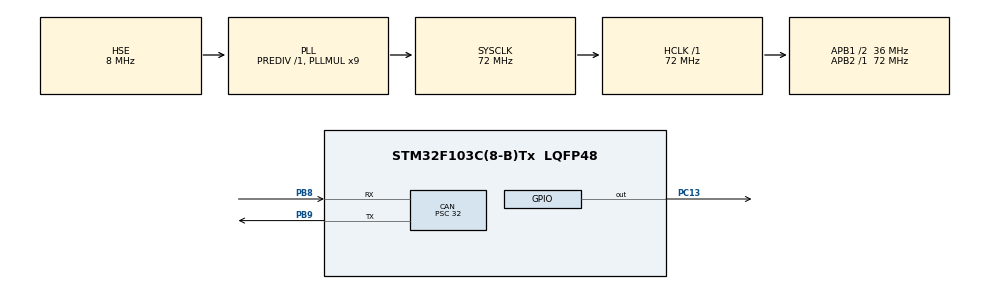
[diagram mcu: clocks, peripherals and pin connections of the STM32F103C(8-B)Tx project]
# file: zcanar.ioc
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CAN.BS1=CAN_BS1_2TQ
CAN.BS2=CAN_BS2_2TQ
CAN.CalculateBaudRate=225000
CAN.CalculateTimeBit=4444
CAN.CalculateTimeQuantum=888.8888888888889
CAN.Prescaler=32
Mcu.Family=STM32F1
Mcu.Name=STM32F103C(8-B)Tx
Mcu.Package=LQFP48
NVIC.CAN1_RX1_IRQn=true\:0\:0\:false\:false\:true\:true\:true\:true
NVIC.PriorityGroup=NVIC_PRIORITYGROUP_4
NVIC.USB_LP_CAN1_RX0_IRQn=true\:0\:0\:false\:false\:true\:true\:true\:true
PA13.Mode=Serial_Wire
PA13.Signal=SYS_JTMS-SWDIO
PA14.Mode=Serial_Wire
PA14.Signal=SYS_JTCK-SWCLK
PB8.Mode=CAN_Activate
PB8.Signal=CAN_RX
PB9.Mode=CAN_Activate
PB9.Signal=CAN_TX
PC13-TAMPER-RTC.Signal=GPIO_Output
PD0-OSC_IN.Mode=HSE-External-Oscillator
PD0-OSC_IN.Signal=RCC_OSC_IN
PD1-OSC_OUT.Mode=HSE-External-Oscillator
PD1-OSC_OUT.Signal=RCC_OSC_OUT
ProjectManager.HeapSize=0x200
ProjectManager.StackSize=0x400
ProjectManager.TargetToolchain=STM32CubeIDE
RCC.AHBFreq_Value=72000000
RCC.APB1CLKDivider=RCC_HCLK_DIV2
RCC.APB1Freq_Value=36000000
RCC.APB1TimFreq_Value=72000000
RCC.APB2Freq_Value=72000000
RCC.APB2TimFreq_Value=72000000
RCC.HCLKFreq_Value=72000000
RCC.PLLMUL=RCC_PLL_MUL9
RCC.PLLSourceVirtual=RCC_PLLSOURCE_HSE
RCC.SYSCLKFreq_VALUE=72000000
RCC.SYSCLKSource=RCC_SYSCLKSOURCE_PLLCLK
RCC.USBFreq_Value=72000000
board=custom

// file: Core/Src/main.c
/* USER CODE BEGIN Header */
/**
  ******************************************************************************
  * @file           : main.c
  * @brief          : Main program body
  ******************************************************************************
  * @attention
  *
  * Copyright (c) 2026 STMicroelectronics.
  * All rights reserved.
  *
  * This software is licensed under terms that can be found in the LICENSE file
  * in the root directory of this software component.
  * If no LICENSE file comes with this software, it is provided AS-IS.
  *
  ******************************************************************************
  */
/* USER CODE END Header */
#include "main.h"

/* USER CODE BEGIN Includes */
#include "stdio.h"
#include "string.h"
/* USER CODE END Includes */

CAN_HandleTypeDef hcan;

void SystemClock_Config(void);
static void MX_GPIO_Init(void);
static void MX_CAN_Init(void);

/* USER CODE BEGIN 0 */

struct controller{
	float P;
	float I;
	float D;
	float vel;
	float pos;
};

uint8_t senderID = 0xe0;

struct controller s1 = {2.0, 1.5, 0.005, 400, 11400};

CAN_TxHeaderTypeDef txHeader;
CAN_RxHeaderTypeDef rxHeader;

uint8_t txData[8];
uint8_t rxData[8];

uint32_t txMailbox;

void HAL_CAN_RxFifo1MsgPendingCallback(CAN_HandleTypeDef *hcan)
{

	HAL_CAN_GetRxMessage(hcan, CAN_RX_FIFO1, &rxHeader, rxData);
	if(rxHeader.RTR && rxHeader.StdId==0x7fe)
	{
		HAL_GPIO_TogglePin(GPIOC, GPIO_PIN_13);
		txHeader.DLC = 8;
		txHeader.IDE = CAN_ID_STD;
		txHeader.RTR = CAN_RTR_DATA;
		txHeader.StdId = 0x7fe;
		memset(txData, (uint8_t []){0,0,0,senderID|0},4);
		memcpy(&txData[4],&s1.P, 4);
		HAL_CAN_AddTxMessage(hcan, &txHeader, txData, &txMailbox);
		memset(txData, (uint8_t []){0,0,0,senderID|1},4);
		memcpy(&txData[4],&s1.I, 4);
		HAL_CAN_AddTxMessage(hcan, &txHeader, txData, &txMailbox);
		memset(txData, (uint8_t []){0,0,0,senderID|2},4);
		memcpy(&txData[4],&s1.D, 4);
		HAL_CAN_AddTxMessage(hcan, &txHeader, txData, &txMailbox);
	}
}

/* USER CODE END 0 */

int main(void)
{

  /* MCU Configuration--------------------------------------------------------*/

  /* Reset of all peripherals, Initializes the Flash interface and the Systick. */
  HAL_Init();

  /* Configure the system clock */
  SystemClock_Config();

  /* Initialize all configured peripherals */
  MX_GPIO_Init();
  MX_CAN_Init();
  /* USER CODE BEGIN 2 */
  HAL_CAN_Start(&hcan);
  /* USER CODE END 2 */

  /* Infinite loop */
  while (1)
  {

  }
}

void SystemClock_Config(void)
{
  RCC_OscInitTypeDef RCC_OscInitStruct = {0};
  RCC_ClkInitTypeDef RCC_ClkInitStruct = {0};

  /** Initializes the RCC Oscillators according to the specified parameters
  * in the RCC_OscInitTypeDef structure.
  */
  RCC_OscInitStruct.OscillatorType = RCC_OSCILLATORTYPE_HSE;
  RCC_OscInitStruct.HSEState = RCC_HSE_ON;
  RCC_OscInitStruct.HSEPredivValue = RCC_HSE_PREDIV_DIV1;
  RCC_OscInitStruct.HSIState = RCC_HSI_ON;
  RCC_OscInitStruct.PLL.PLLState = RCC_PLL_ON;
  RCC_OscInitStruct.PLL.PLLSource = RCC_PLLSOURCE_HSE;
  RCC_OscInitStruct.PLL.PLLMUL = RCC_PLL_MUL9;
  if (HAL_RCC_OscConfig(&RCC_OscInitStruct) != HAL_OK)
  {
    Error_Handler();
  }

  /** Initializes the CPU, AHB and APB buses clocks
  */
  RCC_ClkInitStruct.ClockType = RCC_CLOCKTYPE_HCLK|RCC_CLOCKTYPE_SYSCLK
                              |RCC_CLOCKTYPE_PCLK1|RCC_CLOCKTYPE_PCLK2;
  RCC_ClkInitStruct.SYSCLKSource = RCC_SYSCLKSOURCE_PLLCLK;
  RCC_ClkInitStruct.AHBCLKDivider = RCC_SYSCLK_DIV1;
  RCC_ClkInitStruct.APB1CLKDivider = RCC_HCLK_DIV2;
  RCC_ClkInitStruct.APB2CLKDivider = RCC_HCLK_DIV1;

  if (HAL_RCC_ClockConfig(&RCC_ClkInitStruct, FLASH_LATENCY_2) != HAL_OK)
  {
    Error_Handler();
  }
}

static void MX_CAN_Init(void)
{

  hcan.Instance = CAN1;
  hcan.Init.Prescaler = 32;
  hcan.Init.Mode = CAN_MODE_NORMAL;
  hcan.Init.SyncJumpWidth = CAN_SJW_1TQ;
  hcan.Init.TimeSeg1 = CAN_BS1_2TQ;
  hcan.Init.TimeSeg2 = CAN_BS2_2TQ;
  hcan.Init.TimeTriggeredMode = DISABLE;
  hcan.Init.AutoBusOff = DISABLE;
  hcan.Init.AutoWakeUp = DISABLE;
  hcan.Init.AutoRetransmission = DISABLE;
  hcan.Init.ReceiveFifoLocked = DISABLE;
  hcan.Init.TransmitFifoPriority = DISABLE;
  if (HAL_CAN_Init(&hcan) != HAL_OK)
  {
    Error_Handler();
  }
  /* USER CODE BEGIN CAN_Init 2 */
  CAN_FilterTypeDef myFilter;
  myFilter.FilterActivation = CAN_FILTER_ENABLE;
  myFilter.FilterFIFOAssignment = CAN_FILTER_FIFO1;
  myFilter.FilterBank = 0;
  myFilter.FilterMode = CAN_FILTERMODE_IDMASK;
  myFilter.FilterIdHigh = 0x000<<5;
  myFilter.FilterIdLow = 0;
  myFilter.FilterMaskIdHigh = 0x000<<5;
  myFilter.FilterMaskIdLow = 0;
  myFilter.FilterScale = CAN_FILTERSCALE_32BIT;
  myFilter.SlaveStartFilterBank = 13;
  HAL_CAN_ConfigFilter(&hcan, &myFilter);
  HAL_CAN_ActivateNotification(&hcan, CAN_IT_RX_FIFO1_MSG_PENDING);
  /* USER CODE END CAN_Init 2 */

}

static void MX_GPIO_Init(void)
{
  GPIO_InitTypeDef GPIO_InitStruct = {0};

  /* GPIO Ports Clock Enable */
  __HAL_RCC_GPIOC_CLK_ENABLE();
  __HAL_RCC_GPIOD_CLK_ENABLE();
  __HAL_RCC_GPIOA_CLK_ENABLE();
  __HAL_RCC_GPIOB_CLK_ENABLE();

  /*Configure GPIO pin Output Level */
  HAL_GPIO_WritePin(GPIOC, GPIO_PIN_13, GPIO_PIN_RESET);

  /*Configure GPIO pin : PC13 */
  GPIO_InitStruct.Pin = GPIO_PIN_13;
  GPIO_InitStruct.Mode = GPIO_MODE_OUTPUT_PP;
  GPIO_InitStruct.Pull = GPIO_NOPULL;
  GPIO_InitStruct.Speed = GPIO_SPEED_FREQ_LOW;
  HAL_GPIO_Init(GPIOC, &GPIO_InitStruct);

}

void Error_Handler(void)
{
  __disable_irq();
  while (1)
  {
  }
}
